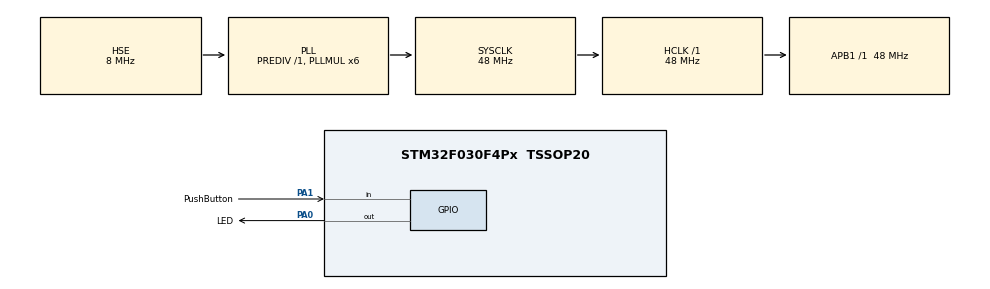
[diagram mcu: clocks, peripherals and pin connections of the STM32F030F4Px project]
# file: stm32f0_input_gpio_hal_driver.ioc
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Mcu.Family=STM32F0
Mcu.Name=STM32F030F4Px
Mcu.Package=TSSOP20
PA0.GPIO_Label=LED
PA0.Signal=GPIO_Output
PA1.GPIO_Label=PushButton
PA1.GPIO_PuPd=GPIO_PULLDOWN
PA1.Signal=GPIO_Input
PA13.Mode=Serial_Wire
PA13.Signal=SYS_SWDIO
PA14.Mode=Serial_Wire
PA14.Signal=SYS_SWCLK
PF0-OSC_IN.Mode=HSE-External-Oscillator
PF0-OSC_IN.Signal=RCC_OSC_IN
PF1-OSC_OUT.Mode=HSE-External-Oscillator
PF1-OSC_OUT.Signal=RCC_OSC_OUT
ProjectManager.HeapSize=0x200
ProjectManager.StackSize=0x400
ProjectManager.TargetToolchain=STM32CubeIDE
RCC.AHBFreq_Value=48000000
RCC.APB1Freq_Value=48000000
RCC.APB1TimFreq_Value=48000000
RCC.EnbaleCSS=true
RCC.HCLKFreq_Value=48000000
RCC.PLLMUL=RCC_PLL_MUL6
RCC.PLLSourceVirtual=RCC_PLLSOURCE_HSE
RCC.SYSCLKFreq_VALUE=48000000
RCC.SYSCLKSource=RCC_SYSCLKSOURCE_PLLCLK
board=custom

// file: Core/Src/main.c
/* USER CODE BEGIN Header */
/**
  ******************************************************************************
  * @file           : main.c
  * @brief          : Main program body
  ******************************************************************************
  * @attention
  *
  * Copyright (c) 2025 STMicroelectronics.
  * All rights reserved.
  *
  * This software is licensed under terms that can be found in the LICENSE file
  * in the root directory of this software component.
  * If no LICENSE file comes with this software, it is provided AS-IS.
  *
  ******************************************************************************
  */
/* USER CODE END Header */
#include "main.h"

void SystemClock_Config(void);
static void MX_GPIO_Init(void);

int main(void)
{

  /* MCU Configuration--------------------------------------------------------*/

  /* Reset of all peripherals, Initializes the Flash interface and the Systick. */
  HAL_Init();

  /* Configure the system clock */
  SystemClock_Config();

  /* Initialize all configured peripherals */
  MX_GPIO_Init();

  /* Infinite loop */
  /* USER CODE BEGIN WHILE */
  while (1)
  {
//	  /* if you pull up push-button pin */
//	  if(HAL_GPIO_ReadPin(PushButton_GPIO_Port, PushButton_Pin) == GPIO_PIN_RESET)
//	  {
//		  /* button pressed */
//		  HAL_GPIO_TogglePin(LED_GPIO_Port, LED_Pin);	/* toggle led to show button pressed */
//		  HAL_Delay(200);		/* for bounce */
//	  }

	  /* if you pull down push-button pin */
	  if(HAL_GPIO_ReadPin(PushButton_GPIO_Port, PushButton_Pin) == GPIO_PIN_SET)
	  {
		  /* button pressed */
		  HAL_GPIO_TogglePin(LED_GPIO_Port, LED_Pin);	/* toggle led to show button pressed */
		  HAL_Delay(200);		/* for bounce */
	  }

    /* USER CODE END WHILE */

  }
}

void SystemClock_Config(void)
{
  RCC_OscInitTypeDef RCC_OscInitStruct = {0};
  RCC_ClkInitTypeDef RCC_ClkInitStruct = {0};

  /** Initializes the RCC Oscillators according to the specified parameters
  * in the RCC_OscInitTypeDef structure.
  */
  RCC_OscInitStruct.OscillatorType = RCC_OSCILLATORTYPE_HSE;
  RCC_OscInitStruct.HSEState = RCC_HSE_ON;
  RCC_OscInitStruct.PLL.PLLState = RCC_PLL_ON;
  RCC_OscInitStruct.PLL.PLLSource = RCC_PLLSOURCE_HSE;
  RCC_OscInitStruct.PLL.PLLMUL = RCC_PLL_MUL6;
  RCC_OscInitStruct.PLL.PREDIV = RCC_PREDIV_DIV1;
  if (HAL_RCC_OscConfig(&RCC_OscInitStruct) != HAL_OK)
  {
    Error_Handler();
  }

  /** Initializes the CPU, AHB and APB buses clocks
  */
  RCC_ClkInitStruct.ClockType = RCC_CLOCKTYPE_HCLK|RCC_CLOCKTYPE_SYSCLK
                              |RCC_CLOCKTYPE_PCLK1;
  RCC_ClkInitStruct.SYSCLKSource = RCC_SYSCLKSOURCE_PLLCLK;
  RCC_ClkInitStruct.AHBCLKDivider = RCC_SYSCLK_DIV1;
  RCC_ClkInitStruct.APB1CLKDivider = RCC_HCLK_DIV1;

  if (HAL_RCC_ClockConfig(&RCC_ClkInitStruct, FLASH_LATENCY_1) != HAL_OK)
  {
    Error_Handler();
  }

  /** Enables the Clock Security System
  */
  HAL_RCC_EnableCSS();
}

static void MX_GPIO_Init(void)
{
  GPIO_InitTypeDef GPIO_InitStruct = {0};

  /* GPIO Ports Clock Enable */
  __HAL_RCC_GPIOF_CLK_ENABLE();
  __HAL_RCC_GPIOA_CLK_ENABLE();

  /*Configure GPIO pin Output Level */
  HAL_GPIO_WritePin(LED_GPIO_Port, LED_Pin, GPIO_PIN_RESET);

  /*Configure GPIO pin : LED_Pin */
  GPIO_InitStruct.Pin = LED_Pin;
  GPIO_InitStruct.Mode = GPIO_MODE_OUTPUT_PP;
  GPIO_InitStruct.Pull = GPIO_NOPULL;
  GPIO_InitStruct.Speed = GPIO_SPEED_FREQ_LOW;
  HAL_GPIO_Init(LED_GPIO_Port, &GPIO_InitStruct);

  /*Configure GPIO pin : PushButton_Pin */
  GPIO_InitStruct.Pin = PushButton_Pin;
  GPIO_InitStruct.Mode = GPIO_MODE_INPUT;
  GPIO_InitStruct.Pull = GPIO_PULLDOWN;
  HAL_GPIO_Init(PushButton_GPIO_Port, &GPIO_InitStruct);

}

void Error_Handler(void)
{
  __disable_irq();
  while (1)
  {
  }
}
